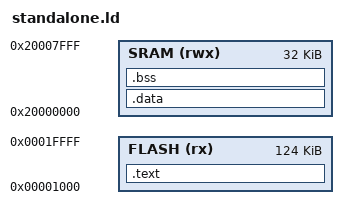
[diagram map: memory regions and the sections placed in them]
/******************************************************************************
standalone.ld - Linker script for applications using startup.c and  DriverLib.

Copyright (C) 2011  busware

This program is free software; you can redistribute it and/or
modify it under the terms of the GNU General Public License
as published by the Free Software Foundation; either version 2
of the License, or (at your option) any later version.

This program is distributed in the hope that it will be useful,
but WITHOUT ANY WARRANTY; without even the implied warranty of
MERCHANTABILITY or FITNESS FOR A PARTICULAR PURPOSE.  See the
GNU General Public License for more details.

You should have received a copy of the GNU General Public License
along with this program; if not, write to the Free Software
Foundation, Inc., 51 Franklin Street, Fifth Floor, Boston, MA  02110-1301, USA.
*************************************************************************/

MEMORY
{
   FLASH (rx) : ORIGIN = 0x00001000, LENGTH = 0x0001F000
   SRAM (rwx) : ORIGIN = 0x20000000, LENGTH = 0x00008000
}

SECTIONS
{
    .text :
    {
        KEEP(*(.isr_vector))
        *(.text*)
        *(.rodata*)
        _etext = .;
    } > FLASH

    .data : AT (ADDR(.text) + SIZEOF(.text))
    {
        _data = .;
        *(vtable)
        *(.data*)
        _edata = .;
    } > SRAM

    .bss :
    {
        _bss = .;
        *(.bss*)
        *(COMMON)
        _ebss = .;
    } > SRAM
PROVIDE(__HEAP_START = _ebss );
}
